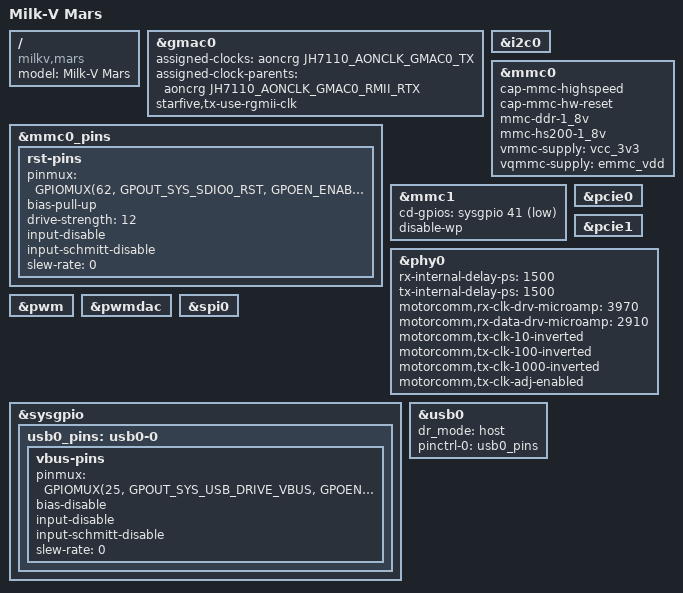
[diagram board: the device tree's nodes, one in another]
// SPDX-License-Identifier: GPL-2.0 OR MIT
/*
 * Copyright (C) 2023 Jisheng Zhang <jszhang@kernel.org>
 */

/dts-v1/;
#include "jh7110-common.dtsi"

/ {
	model = "Milk-V Mars";
	compatible = "milkv,mars", "starfive,jh7110";
};

&gmac0 {
	assigned-clocks = <&aoncrg JH7110_AONCLK_GMAC0_TX>;
	assigned-clock-parents = <&aoncrg JH7110_AONCLK_GMAC0_RMII_RTX>;
	starfive,tx-use-rgmii-clk;
	status = "okay";
};

&i2c0 {
	status = "okay";
};

&mmc0 {
	cap-mmc-highspeed;
	cap-mmc-hw-reset;
	mmc-ddr-1_8v;
	mmc-hs200-1_8v;
	vmmc-supply = <&vcc_3v3>;
	vqmmc-supply = <&emmc_vdd>;
};

&mmc0_pins {
	 rst-pins {
		pinmux = <GPIOMUX(62, GPOUT_SYS_SDIO0_RST,
				      GPOEN_ENABLE,
				      GPI_NONE)>;
		bias-pull-up;
		drive-strength = <12>;
		input-disable;
		input-schmitt-disable;
		slew-rate = <0>;
	};
};

&mmc1 {
	cd-gpios = <&sysgpio 41 GPIO_ACTIVE_LOW>;
	disable-wp;
};

&pcie0 {
	status = "okay";
};

&pcie1 {
	status = "okay";
};

&phy0 {
	rx-internal-delay-ps = <1500>;
	tx-internal-delay-ps = <1500>;
	motorcomm,rx-clk-drv-microamp = <3970>;
	motorcomm,rx-data-drv-microamp = <2910>;
	motorcomm,tx-clk-10-inverted;
	motorcomm,tx-clk-100-inverted;
	motorcomm,tx-clk-1000-inverted;
	motorcomm,tx-clk-adj-enabled;
};

&pwm {
	status = "okay";
};

&pwmdac {
	status = "okay";
};

&spi0 {
	status = "okay";
};

&sysgpio {
	usb0_pins: usb0-0 {
		vbus-pins {
			pinmux = <GPIOMUX(25, GPOUT_SYS_USB_DRIVE_VBUS,
					      GPOEN_ENABLE,
					      GPI_NONE)>;
			bias-disable;
			input-disable;
			input-schmitt-disable;
			slew-rate = <0>;
		};
	};
};

&usb0 {
	dr_mode = "host";
	pinctrl-names = "default";
	pinctrl-0 = <&usb0_pins>;
	status = "okay";
};
